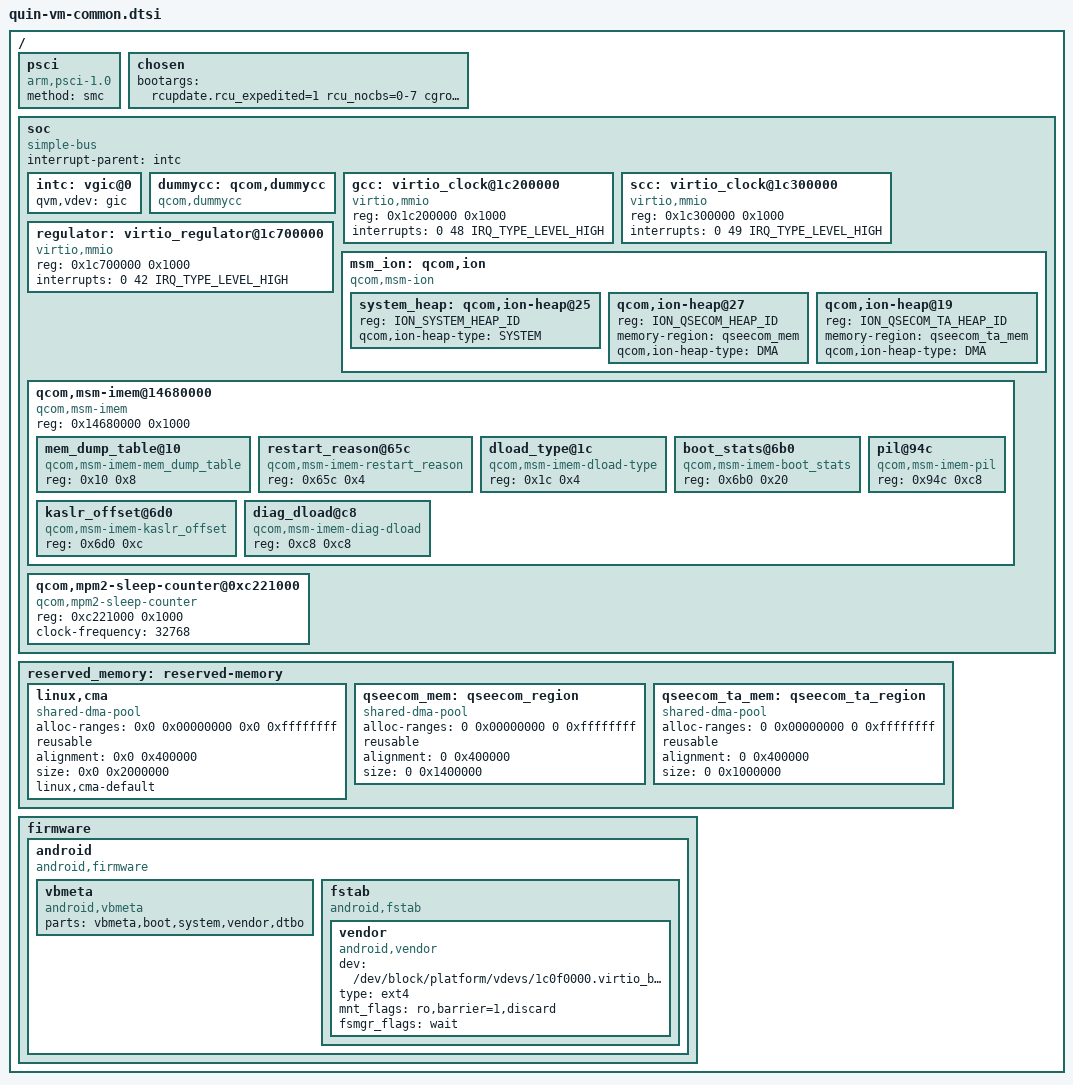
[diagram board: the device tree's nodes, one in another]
#include <dt-bindings/arm/msm/msm_ion_ids.h>

/ {
	#address-cells = <2>;
	#size-cells = <2>;

	psci {
		compatible = "arm,psci-1.0";
		method = "smc";
	};

	chosen {
		bootargs = "rcupdate.rcu_expedited=1 rcu_nocbs=0-7 cgroup.memory=nokmem,nosocket";
	};

	soc: soc { };

	reserved_memory: reserved-memory {
		#address-cells = <2>;
		#size-cells = <2>;
		ranges;

		/* global autoconfigured region for contiguous allocations */
		linux,cma {
			compatible = "shared-dma-pool";
			alloc-ranges = <0x0 0x00000000 0x0 0xffffffff>;
			reusable;
			alignment = <0x0 0x400000>;
			size = <0x0 0x2000000>;
			linux,cma-default;
		};

		qseecom_mem: qseecom_region {
			compatible = "shared-dma-pool";
			alloc-ranges = <0 0x00000000 0 0xffffffff>;
			reusable;
			alignment = <0 0x400000>;
			size = <0 0x1400000>;
		};

		qseecom_ta_mem: qseecom_ta_region {
			compatible = "shared-dma-pool";
			alloc-ranges = <0 0x00000000 0 0xffffffff>;
			reusable;
			alignment = <0 0x400000>;
			size = <0 0x1000000>;
		};
	};

	firmware: firmware {
		android {
			compatible = "android,firmware";
			vbmeta {
				compatible = "android,vbmeta";
				parts = "vbmeta,boot,system,vendor,dtbo";
			};

			fstab {
				compatible = "android,fstab";
				vendor {
					compatible = "android,vendor";
					dev="/dev/block/platform/vdevs/1c0f0000.virtio_blk/vdc";
					type = "ext4";
					mnt_flags = "ro,barrier=1,discard";
					fsmgr_flags = "wait";
					status = "ok";
				};
			};
		};
	};
};

&soc {
	#address-cells = <1>;
	#size-cells = <1>;
	interrupt-parent = <&intc>;
	ranges = <0 0 0 0xffffffff>;
	compatible = "simple-bus";

	intc: vgic@0 {
		qvm,vdev = "gic";
	};

	dummycc: qcom,dummycc {
		compatible = "qcom,dummycc";
		#clock-cells = <1>;
		#reset-cells = <1>;
	};

	gcc: virtio_clock@1c200000 {
		compatible = "virtio,mmio";
		reg = <0x1c200000 0x1000>;
		interrupts = <0 48 IRQ_TYPE_LEVEL_HIGH>;
		#clock-cells = <1>;
		#reset-cells = <1>;
	};

	scc: virtio_clock@1c300000 {
		compatible = "virtio,mmio";
		reg = <0x1c300000 0x1000>;
		interrupts = <0 49 IRQ_TYPE_LEVEL_HIGH>;
		#clock-cells = <1>;
	};

	regulator: virtio_regulator@1c700000 {
		compatible = "virtio,mmio";
		reg = <0x1c700000 0x1000>;
		interrupts = <0 42 IRQ_TYPE_LEVEL_HIGH>;
	};

	msm_ion: qcom,ion {
		compatible = "qcom,msm-ion";
		#address-cells = <1>;
		#size-cells = <0>;

		system_heap: qcom,ion-heap@25 {
			reg = <ION_SYSTEM_HEAP_ID>;
			qcom,ion-heap-type = "SYSTEM";
		};

		qcom,ion-heap@27 { /* QSEECOM HEAP */
			reg = <ION_QSECOM_HEAP_ID>;
			memory-region = <&qseecom_mem>;
			qcom,ion-heap-type = "DMA";
		};

		qcom,ion-heap@19 { /* QSEECOM TA HEAP */
			reg = <ION_QSECOM_TA_HEAP_ID>;
			memory-region = <&qseecom_ta_mem>;
			qcom,ion-heap-type = "DMA";
		};
	};

	qcom,msm-imem@14680000 {
		compatible = "qcom,msm-imem";
		reg = <0x14680000 0x1000>;
		ranges = <0x0 0x14680000 0x1000>;
		#address-cells = <1>;
		#size-cells = <1>;

		mem_dump_table@10 {
			compatible = "qcom,msm-imem-mem_dump_table";
			reg = <0x10 0x8>;
		};

		restart_reason@65c {
			compatible = "qcom,msm-imem-restart_reason";
			reg = <0x65c 0x4>;
		};

		dload_type@1c {
			compatible = "qcom,msm-imem-dload-type";
			reg = <0x1c 0x4>;
		};

		boot_stats@6b0 {
			compatible = "qcom,msm-imem-boot_stats";
			reg = <0x6b0 0x20>;
		};

		kaslr_offset@6d0 {
			compatible = "qcom,msm-imem-kaslr_offset";
			reg = <0x6d0 0xc>;
		};

		pil@94c {
			compatible = "qcom,msm-imem-pil";
			reg = <0x94c 0xc8>;
		};

		diag_dload@c8 {
			compatible = "qcom,msm-imem-diag-dload";
			reg = <0xc8 0xc8>;
		};
	};

	qcom,mpm2-sleep-counter@0xc221000 {
		compatible = "qcom,mpm2-sleep-counter";
		reg = <0xc221000 0x1000>;
		clock-frequency = <32768>;
	};
};
